# PIC32CK1025SG01100 device description
Architecture: CORTEX-M33; Family: PIC32CK; Series: PIC32CKSG01
Registers are 32-bit, read-write, reset 0x0 unless marked. A register's access mark holds for its fields unless they carry their own. Offsets are from the block's base; [hi:lo] are bit positions; lines under a group give offsets from that group; {n}, {i} and the like mark numbered series; 'fields as' and 'values as' point back to an identical list.

## FUSES_DALCFG — Defines FUSE parameters
Instances: FUSES_DALCFG 0x0A004000
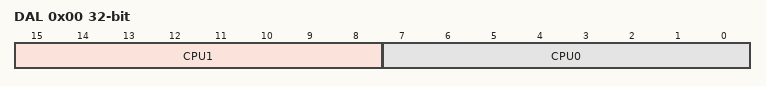
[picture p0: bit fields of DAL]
0x00 DAL — Debug Access Level
  [15:8] CPU1 — HSM DAL Elevation Value
    129=DAL0 (FCW_DAL0_VALUE); 153=DAL1 (FCW_DAL1_VALUE); 219=DAL2 (FCW_DAL2_VALUE)
  [7:0] CPU0 — Host DAL Elevation Value
    values as CPU1

## FUSES_CALOTP — Defines FUSE parameters
Instances: FUSES_CALOTP 0x0A007000
0x180 FCCFG64 ro reset not defined — PTC Calibration
  [15:0] PTCFG0
0x184 FCCFG65 ro reset not defined — ADC Calibration
  [31:0] ADCFG0
0x188 FCCFG66 ro reset not defined — Comparator Calibration
  [7:0] ACPAIR_SEL
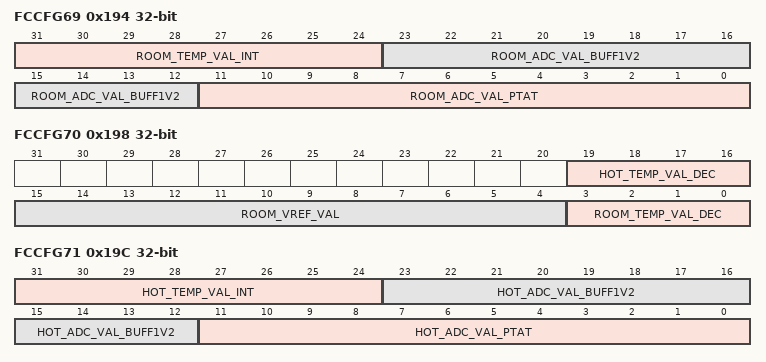
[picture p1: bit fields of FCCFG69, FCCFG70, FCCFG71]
0x194 FCCFG69 ro reset not defined — Temperature calibration values 0
  [31:24] ROOM_TEMP_VAL_INT, [23:12] ROOM_ADC_VAL_BUFF1V2, [11:0] ROOM_ADC_VAL_PTAT
0x198 FCCFG70 ro reset not defined — Temperature calibration values 1
  [19:16] HOT_TEMP_VAL_DEC, [15:4] ROOM_VREF_VAL, [3:0] ROOM_TEMP_VAL_DEC
0x19C FCCFG71 ro reset not defined — Temperature calibration values 2
  [31:24] HOT_TEMP_VAL_INT, [23:12] HOT_ADC_VAL_BUFF1V2, [11:0] HOT_ADC_VAL_PTAT
0x1A0 FCCFG72 ro reset not defined — MAC ID (31 through 0)
  [31:0] FMAC_31_0
0x1A4 FCCFG73 ro reset not defined — MAC ID (47 through 32)
  [15:0] FMAC_47_32

## GCLK — Generic Clock Generator
Instances: GCLK 0x44010000
0x00 CTRLA 8-bit (WSYNC) — Control
  [0] SWRST — Software Reset
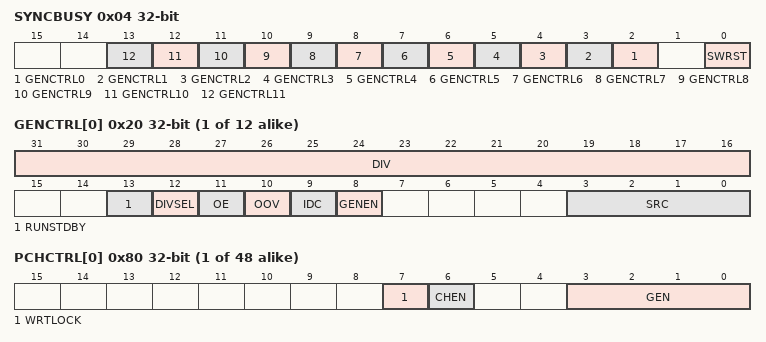
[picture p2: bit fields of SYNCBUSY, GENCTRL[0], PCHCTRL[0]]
0x04 SYNCBUSY ro — Synchronization Busy
  [n+2] GENCTRL{n} (n=0..11) — Generic Clock Generator Control {n} Synchronization Busy bit
  [0] SWRST — Software Reset Synchronization Busy bit
{0x20+4i} GENCTRL[{i}] (i=0..11) (WSYNC) — Generic Clock Generator Control
  [31:16] DIV — Division Factor
  [13] RUNSTDBY — Run in Standby
  [12] DIVSEL — Divide Selection
    0=DIV1 (Divide input directly by divider factor); 1=DIV2 (Divide input by 2^(divider factor+ 1))
  [11] OE — Output Enable
  [10] OOV — Output Off Value
  [9] IDC — Improve Duty Cycle
  [8] GENEN — Generic Clock Generator Enable
  [3:0] SRC — Source Select
    0=XOSC (XOSC0 oscillator output); 1=GCLKIN (Generator input pad); 2=GCLKGEN1 (Generic clock generator 1 output); 3=OSCULP32K (OSCULP32K oscillator output); 4=XOSC32K (XOSC32K oscillator output); 5=DFLL (DFLL output); 6=PLL0_0 (Frac Divider PLL0 output 0); {v}=PLL0_{v-6} (PLL0 output {v-6}) (v=7..11)
{0x80+4i} PCHCTRL[{i}] (i=0..47) — Peripheral Clock Control
  [7] WRTLOCK — Write Lock
  [6] CHEN — Channel Enable
  [3:0] GEN — Generic Clock Generator
    {v}=GCLK{v} (Generic clock generator {v}) (v=0..11)

## HMATRIX2 — HSB Matrix
Instances: HMATRIX 0x44806000
{0x0+4i} MCFG[{i}] (i=0..15) reset 0x2 — Master Configuration
  [2:0] ULBT — Undefined Length Burst Type
    0=INFINITE (Infinite Length); 1=SINGLE (Single Access); 2=FOUR_BEAT (Four Beat Burst); 3=EIGHT_BEAT (Eight Beat Burst); 4=SIXTEEN_BEAT (Sixteen Beat Burst)
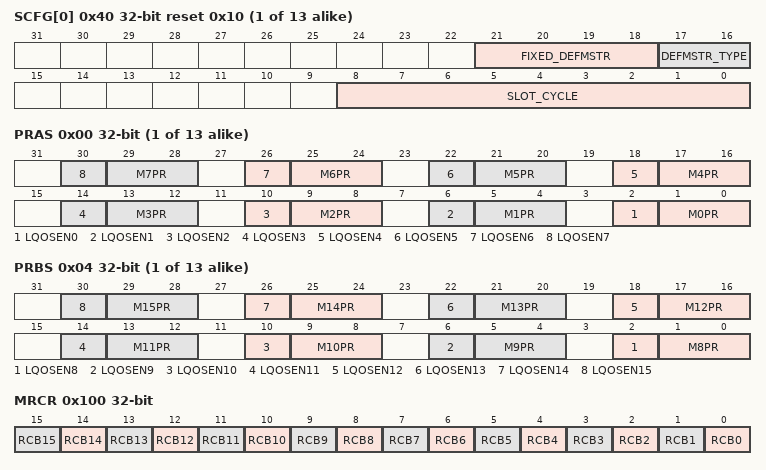
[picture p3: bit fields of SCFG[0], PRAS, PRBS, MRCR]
{0x40+4i} SCFG[{i}] (i=0..12) reset 0x10 — Slave Configuration
  [21:18] FIXED_DEFMSTR — Fixed Index of Default Master
  [17:16] DEFMSTR_TYPE — Default Master Type
    0=NO_DEFAULT (No Default Master. At the end of current slave access, if no other master request is pending, the slave is deconnected from all masters. This resusts in having a one cycle latency for the first transfer of a burst.); 1=LAST_DEFAULT (Last Default Master At the end of current slave access, if no other master request is pending, the slave stay connected with the last master havingaccessed it.This resusts in not having the one cycle latency when the last master re-trying access on the slave.); 2=FIXED_DEFAULT (Fixed Default Master At the end of current slave access, if no other master request is pending, the slave connects with fixed master which numberis in FIXED_DEFMSTR register.This resusts in not having the one cycle latency when the fixed master re-trying access on the slave.)
  [8:0] SLOT_CYCLE — Maximum Number of Allowed Cycles for a Burst
{0x80+8i} PRS[{i}] (i=0..12) group
  0x00 PRAS — Priority A for Slave
    [4n+2] LQOSEN{n} (n=0..7) — Latency Quality Of Service Enable for Master {n}
    [4n+1:4n] M{n}PR (n=0..7) — Master {n} Priority
  0x04 PRBS — Priority B for Slave
    [4n-30] LQOSEN{n} (n=8..15) — Latency Quality Of Service Enable for Master {n}
    [4n-31:4n-32] M{n}PR (n=8..15) — Master {n} Priority
0x100 MRCR — Master Remap Control
  [all] fields
    0=DIS (Disable remapped address decoding for master); 1=ENA (Enable remapped address decoding for master)
  [n] RCB{n} (n=0..15) — Remap Command Bit for Master {n}
{0x110+4i} SFR[{i}] (i=0..12) — Special Function
  [31:0] SFR — Special Function Register
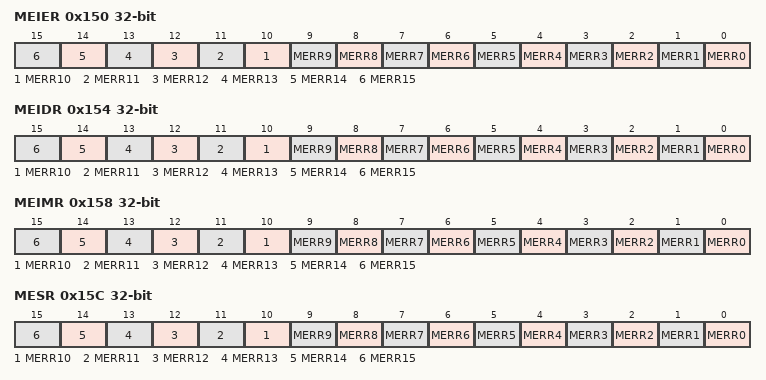
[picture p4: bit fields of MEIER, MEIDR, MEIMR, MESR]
0x150 MEIER wo reset not defined (atomic set of MEIMR) — Master Error Interrupt Enable
  [n] MERR{n} (n=0..15) — Master {n} Access Error
0x154 MEIDR wo reset not defined (atomic clear of MEIMR) — Master Error Interrupt Disable
  [n] MERR{n} (n=0..15) — Master {n} Access Error
0x158 MEIMR ro reset not defined — Master Error Interrupt Mask
  [n] MERR{n} (n=0..15) — Master {n} Access Error
0x15C MESR ro reset not defined (atomic clear) — Master Error Status
  [n] MERR{n} (n=0..15) — Master {n} Access Error
{0x160+4i} MEAR[{i}] (i=0..15) ro reset not defined — Master Error Address

## Notices in the file
Copyright (c) 2021 Microchip Technology Inc.
SPDX-License-Identifier: Apache-2.0
Licensed under the Apache License, Version 2.0 (the "License");
you may not use this file except in compliance with the License.
You may obtain a copy of the License at
http://www.apache.org/licenses/LICENSE-2.0
Unless required by applicable law or agreed to in writing, software
distributed under the License is distributed on an "AS IS" BASIS,
WITHOUT WARRANTIES OR CONDITIONS OF ANY KIND, either express or implied.
See the License for the specific language governing permissions and
limitations under the License.
